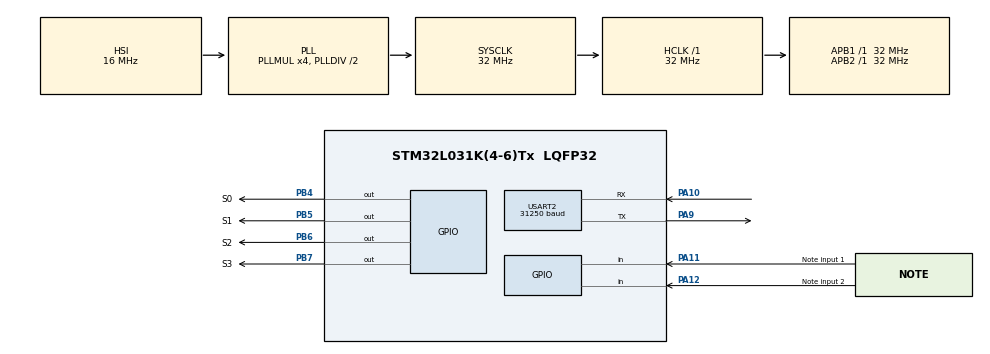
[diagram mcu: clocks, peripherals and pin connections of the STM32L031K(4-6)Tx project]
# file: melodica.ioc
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Mcu.Family=STM32L0
Mcu.Name=STM32L031K(4-6)Tx
Mcu.Package=LQFP32
PA10.Mode=Asynchronous
PA10.Signal=USART2_RX
PA11.GPIO_Label=Note input 1
PA11.GPIO_PuPd=GPIO_PULLDOWN
PA11.Signal=GPIO_Input
PA12.GPIO_Label=Note input 2
PA12.GPIO_PuPd=GPIO_PULLDOWN
PA12.Signal=GPIO_Input
PA13.Mode=Serial_Wire
PA13.Signal=SYS_SWDIO
PA14.Mode=Serial_Wire
PA14.Signal=SYS_SWCLK
PA9.Mode=Asynchronous
PA9.Signal=USART2_TX
PB4.GPIO_Label=S0
PB4.GPIO_PuPd=GPIO_PULLDOWN
PB4.Signal=GPIO_Output
PB5.GPIO_Label=S1
PB5.GPIO_PuPd=GPIO_PULLDOWN
PB5.Signal=GPIO_Output
PB6.GPIO_Label=S2
PB6.GPIO_PuPd=GPIO_PULLDOWN
PB6.Signal=GPIO_Output
PB7.GPIO_Label=S3
PB7.GPIO_PuPd=GPIO_PULLDOWN
PB7.Signal=GPIO_Output
ProjectManager.HeapSize=0x200
ProjectManager.StackSize=0x400
ProjectManager.TargetToolchain=STM32CubeIDE
RCC.AHBFreq_Value=32000000
RCC.APB1Freq_Value=32000000
RCC.APB1TimFreq_Value=32000000
RCC.APB2Freq_Value=32000000
RCC.APB2TimFreq_Value=32000000
RCC.HCLKFreq_Value=32000000
RCC.HSE_VALUE=8000000
RCC.HSI16_VALUE=16000000
RCC.HSI_VALUE=16000000
RCC.LSE_VALUE=32768
RCC.MSI_VALUE=2097000
RCC.PLLMUL=RCC_PLLMUL_4
RCC.SYSCLKFreq_VALUE=32000000
RCC.SYSCLKSource=RCC_SYSCLKSOURCE_PLLCLK
RCC.VCOOutputFreq_Value=64000000
TIM2.Prescaler=72-1
USART2.BaudRate=31250
USART2.VirtualMode-Asynchronous=VM_ASYNC
VP_TIM2_VS_ClockSourceINT.Mode=Internal
board=custom

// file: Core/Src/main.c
/* USER CODE BEGIN Header */
/**
  ******************************************************************************
  * @file           : main.c
  * @brief          : Main program body
  ******************************************************************************
  * @attention
  *
  * Copyright (c) 2025 STMicroelectronics.
  * All rights reserved.
  *
  * This software is licensed under terms that can be found in the LICENSE file
  * in the root directory of this software component.
  * If no LICENSE file comes with this software, it is provided AS-IS.
  *
  ******************************************************************************
  */
/* USER CODE END Header */
#include "main.h"

/* USER CODE BEGIN Includes */
#include "midi.h"

/* USER CODE END Includes */

TIM_HandleTypeDef htim2;

UART_HandleTypeDef huart2;

void SystemClock_Config(void);
static void MX_GPIO_Init(void);
static void MX_USART2_UART_Init(void);
static void MX_TIM2_Init(void);

int main(void)
{

  /* MCU Configuration--------------------------------------------------------*/

  /* Reset of all peripherals, Initializes the Flash interface and the Systick. */
  HAL_Init();

  /* Configure the system clock */
  SystemClock_Config();

  /* Initialize all configured peripherals */
  MX_GPIO_Init();
  MX_USART2_UART_Init();
  MX_TIM2_Init();

  /* Infinite loop */
  /* USER CODE BEGIN WHILE */

  HAL_TIM_Base_Start(&htim2);

  uint8_t notes[32];
  while (1)
  {
	  ReadKeyboard(notes);
    /* USER CODE END WHILE */

  }
}

void SystemClock_Config(void)
{
  RCC_OscInitTypeDef RCC_OscInitStruct = {0};
  RCC_ClkInitTypeDef RCC_ClkInitStruct = {0};
  RCC_PeriphCLKInitTypeDef PeriphClkInit = {0};

  /** Configure the main internal regulator output voltage
  */
  __HAL_PWR_VOLTAGESCALING_CONFIG(PWR_REGULATOR_VOLTAGE_SCALE1);

  /** Initializes the RCC Oscillators according to the specified parameters
  * in the RCC_OscInitTypeDef structure.
  */
  RCC_OscInitStruct.OscillatorType = RCC_OSCILLATORTYPE_HSI;
  RCC_OscInitStruct.HSIState = RCC_HSI_ON;
  RCC_OscInitStruct.HSICalibrationValue = RCC_HSICALIBRATION_DEFAULT;
  RCC_OscInitStruct.PLL.PLLState = RCC_PLL_ON;
  RCC_OscInitStruct.PLL.PLLSource = RCC_PLLSOURCE_HSI;
  RCC_OscInitStruct.PLL.PLLMUL = RCC_PLLMUL_4;
  RCC_OscInitStruct.PLL.PLLDIV = RCC_PLLDIV_2;
  if (HAL_RCC_OscConfig(&RCC_OscInitStruct) != HAL_OK)
  {
    Error_Handler();
  }

  /** Initializes the CPU, AHB and APB buses clocks
  */
  RCC_ClkInitStruct.ClockType = RCC_CLOCKTYPE_HCLK|RCC_CLOCKTYPE_SYSCLK
                              |RCC_CLOCKTYPE_PCLK1|RCC_CLOCKTYPE_PCLK2;
  RCC_ClkInitStruct.SYSCLKSource = RCC_SYSCLKSOURCE_PLLCLK;
  RCC_ClkInitStruct.AHBCLKDivider = RCC_SYSCLK_DIV1;
  RCC_ClkInitStruct.APB1CLKDivider = RCC_HCLK_DIV1;
  RCC_ClkInitStruct.APB2CLKDivider = RCC_HCLK_DIV1;

  if (HAL_RCC_ClockConfig(&RCC_ClkInitStruct, FLASH_LATENCY_1) != HAL_OK)
  {
    Error_Handler();
  }
  PeriphClkInit.PeriphClockSelection = RCC_PERIPHCLK_USART2;
  PeriphClkInit.Usart2ClockSelection = RCC_USART2CLKSOURCE_PCLK1;
  if (HAL_RCCEx_PeriphCLKConfig(&PeriphClkInit) != HAL_OK)
  {
    Error_Handler();
  }
}

static void MX_TIM2_Init(void)
{

  TIM_ClockConfigTypeDef sClockSourceConfig = {0};
  TIM_MasterConfigTypeDef sMasterConfig = {0};

  htim2.Instance = TIM2;
  htim2.Init.Prescaler = 72-1;
  htim2.Init.CounterMode = TIM_COUNTERMODE_UP;
  htim2.Init.Period = 65535;
  htim2.Init.ClockDivision = TIM_CLOCKDIVISION_DIV1;
  htim2.Init.AutoReloadPreload = TIM_AUTORELOAD_PRELOAD_DISABLE;
  if (HAL_TIM_Base_Init(&htim2) != HAL_OK)
  {
    Error_Handler();
  }
  sClockSourceConfig.ClockSource = TIM_CLOCKSOURCE_INTERNAL;
  if (HAL_TIM_ConfigClockSource(&htim2, &sClockSourceConfig) != HAL_OK)
  {
    Error_Handler();
  }
  sMasterConfig.MasterOutputTrigger = TIM_TRGO_RESET;
  sMasterConfig.MasterSlaveMode = TIM_MASTERSLAVEMODE_DISABLE;
  if (HAL_TIMEx_MasterConfigSynchronization(&htim2, &sMasterConfig) != HAL_OK)
  {
    Error_Handler();
  }

}

static void MX_USART2_UART_Init(void)
{

  huart2.Instance = USART2;
  huart2.Init.BaudRate = 31250;
  huart2.Init.WordLength = UART_WORDLENGTH_8B;
  huart2.Init.StopBits = UART_STOPBITS_1;
  huart2.Init.Parity = UART_PARITY_NONE;
  huart2.Init.Mode = UART_MODE_TX_RX;
  huart2.Init.HwFlowCtl = UART_HWCONTROL_NONE;
  huart2.Init.OverSampling = UART_OVERSAMPLING_16;
  huart2.Init.OneBitSampling = UART_ONE_BIT_SAMPLE_DISABLE;
  huart2.AdvancedInit.AdvFeatureInit = UART_ADVFEATURE_NO_INIT;
  if (HAL_UART_Init(&huart2) != HAL_OK)
  {
    Error_Handler();
  }

}

static void MX_GPIO_Init(void)
{
  GPIO_InitTypeDef GPIO_InitStruct = {0};

  /* GPIO Ports Clock Enable */
  __HAL_RCC_GPIOA_CLK_ENABLE();
  __HAL_RCC_GPIOB_CLK_ENABLE();

  /*Configure GPIO pin Output Level */
  HAL_GPIO_WritePin(GPIOB, S0_Pin|S1_Pin|S2_Pin|S3_Pin, GPIO_PIN_RESET);

  /*Configure GPIO pins : Note_input_1_Pin Note_input_2_Pin */
  GPIO_InitStruct.Pin = Note_input_1_Pin|Note_input_2_Pin;
  GPIO_InitStruct.Mode = GPIO_MODE_INPUT;
  GPIO_InitStruct.Pull = GPIO_PULLDOWN;
  HAL_GPIO_Init(GPIOA, &GPIO_InitStruct);

  /*Configure GPIO pins : S0_Pin S1_Pin S2_Pin S3_Pin */
  GPIO_InitStruct.Pin = S0_Pin|S1_Pin|S2_Pin|S3_Pin;
  GPIO_InitStruct.Mode = GPIO_MODE_OUTPUT_PP;
  GPIO_InitStruct.Pull = GPIO_PULLDOWN;
  GPIO_InitStruct.Speed = GPIO_SPEED_FREQ_LOW;
  HAL_GPIO_Init(GPIOB, &GPIO_InitStruct);

}

void Error_Handler(void)
{
  __disable_irq();
  while (1)
  {
  }
}
